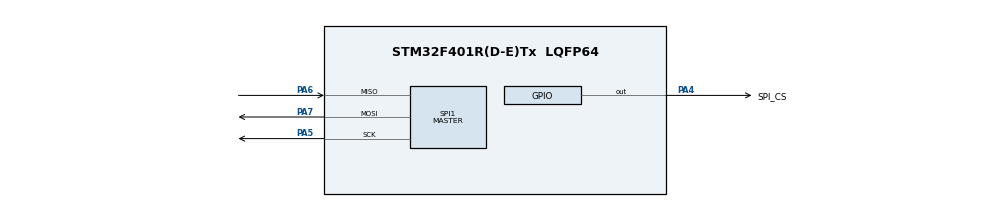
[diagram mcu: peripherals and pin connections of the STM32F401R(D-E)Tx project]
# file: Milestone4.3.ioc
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Mcu.Family=STM32F4
Mcu.Name=STM32F401R(D-E)Tx
Mcu.Package=LQFP64
NVIC.PriorityGroup=NVIC_PRIORITYGROUP_4
PA4.GPIO_Label=SPI_CS
PA4.GPIO_Speed=GPIO_SPEED_FREQ_VERY_HIGH
PA4.PinState=GPIO_PIN_SET
PA4.Signal=GPIO_Output
PA5.Mode=Full_Duplex_Master
PA5.Signal=SPI1_SCK
PA6.Mode=Full_Duplex_Master
PA6.Signal=SPI1_MISO
PA7.Mode=Full_Duplex_Master
PA7.Signal=SPI1_MOSI
ProjectManager.HeapSize=0x200
ProjectManager.StackSize=0x400
ProjectManager.TargetToolchain=Makefile
RCC.AHBFreq_Value=16000000
RCC.APB1Freq_Value=16000000
RCC.APB2Freq_Value=16000000
RCC.CortexFreq_Value=16000000
RCC.HSE_VALUE=25000000
RCC.HSI_VALUE=16000000
RCC.LSE_VALUE=32768
RCC.SYSCLKFreq_VALUE=16000000
RCC.VCOOutputFreq_Value=192000000
SPI1.Direction=SPI_DIRECTION_2LINES
SPI1.Mode=SPI_MODE_MASTER
SPI1.VirtualType=VM_MASTER
board=custom

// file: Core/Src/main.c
/* USER CODE BEGIN Header */
/**
  ******************************************************************************
  * @file           : main.c
  * @brief          : Main program body
  ******************************************************************************
  * @attention
  *
  * Copyright (c) 2026 STMicroelectronics.
  * All rights reserved.
  *
  * This software is licensed under terms that can be found in the LICENSE file
  * in the root directory of this software component.
  * If no LICENSE file comes with this software, it is provided AS-IS.
  *
  ******************************************************************************
  */
/* USER CODE END Header */
#include "main.h"

void SystemClock_Config(void);
static void MX_GPIO_Init(void);
static void MX_SPI1_Init(void);

int main(void)
{

  /* MCU Configuration--------------------------------------------------------*/

  /* Reset of all peripherals, Initializes the Flash interface and the Systick. */
  LL_APB2_GRP1_EnableClock(LL_APB2_GRP1_PERIPH_SYSCFG);
  LL_APB1_GRP1_EnableClock(LL_APB1_GRP1_PERIPH_PWR);

  /* System interrupt init*/
  NVIC_SetPriorityGrouping(NVIC_PRIORITYGROUP_4);

  /* SysTick_IRQn interrupt configuration */
  NVIC_SetPriority(SysTick_IRQn, NVIC_EncodePriority(NVIC_GetPriorityGrouping(),15, 0));

  /* Configure the system clock */
  SystemClock_Config();

  /* Initialize all configured peripherals */
  MX_GPIO_Init();
  MX_SPI1_Init();
  /* USER CODE BEGIN 2 */
  LL_SPI_Enable(SPI1);
  /* USER CODE END 2 */

  const uint8_t data = 0x02;
  /* Infinite loop */
  /* USER CODE BEGIN WHILE */
  while (1)
  {
    LL_GPIO_ResetOutputPin(GPIOA, LL_GPIO_PIN_4);
    /* USER CODE END WHILE */
    while (!LL_SPI_IsActiveFlag_TXE(SPI1)){}
      LL_SPI_TransmitData8(SPI1, data);

    while (!LL_SPI_IsActiveFlag_TXE(SPI1)){}
    while (LL_SPI_IsActiveFlag_BSY(SPI1)){}
    LL_GPIO_SetOutputPin(GPIOA, LL_GPIO_PIN_4);
    LL_mDelay(2000);
  }
  /* USER CODE END 3 */
}

void SystemClock_Config(void)
{
  LL_FLASH_SetLatency(LL_FLASH_LATENCY_0);
  while(LL_FLASH_GetLatency()!= LL_FLASH_LATENCY_0)
  {
  }
  LL_PWR_SetRegulVoltageScaling(LL_PWR_REGU_VOLTAGE_SCALE2);
  LL_RCC_HSI_SetCalibTrimming(16);
  LL_RCC_HSI_Enable();

   /* Wait till HSI is ready */
  while(LL_RCC_HSI_IsReady() != 1)
  {

  }
  LL_RCC_SetAHBPrescaler(LL_RCC_SYSCLK_DIV_1);
  LL_RCC_SetAPB1Prescaler(LL_RCC_APB1_DIV_1);
  LL_RCC_SetAPB2Prescaler(LL_RCC_APB2_DIV_1);
  LL_RCC_SetSysClkSource(LL_RCC_SYS_CLKSOURCE_HSI);

   /* Wait till System clock is ready */
  while(LL_RCC_GetSysClkSource() != LL_RCC_SYS_CLKSOURCE_STATUS_HSI)
  {

  }
  LL_Init1msTick(16000000);
  LL_SetSystemCoreClock(16000000);
  LL_RCC_SetTIMPrescaler(LL_RCC_TIM_PRESCALER_TWICE);
}

static void MX_SPI1_Init(void)
{

  LL_SPI_InitTypeDef SPI_InitStruct = {0};

  LL_GPIO_InitTypeDef GPIO_InitStruct = {0};

  /* Peripheral clock enable */
  LL_APB2_GRP1_EnableClock(LL_APB2_GRP1_PERIPH_SPI1);

  LL_AHB1_GRP1_EnableClock(LL_AHB1_GRP1_PERIPH_GPIOA);
  /**SPI1 GPIO Configuration
  PA5   ------> SPI1_SCK
  PA6   ------> SPI1_MISO
  PA7   ------> SPI1_MOSI
  */
  GPIO_InitStruct.Pin = LL_GPIO_PIN_5|LL_GPIO_PIN_6|LL_GPIO_PIN_7;
  GPIO_InitStruct.Mode = LL_GPIO_MODE_ALTERNATE;
  GPIO_InitStruct.Speed = LL_GPIO_SPEED_FREQ_VERY_HIGH;
  GPIO_InitStruct.OutputType = LL_GPIO_OUTPUT_PUSHPULL;
  GPIO_InitStruct.Pull = LL_GPIO_PULL_NO;
  GPIO_InitStruct.Alternate = LL_GPIO_AF_5;
  LL_GPIO_Init(GPIOA, &GPIO_InitStruct);

  /* SPI1 parameter configuration*/
  SPI_InitStruct.TransferDirection = LL_SPI_FULL_DUPLEX;
  SPI_InitStruct.Mode = LL_SPI_MODE_MASTER;
  SPI_InitStruct.DataWidth = LL_SPI_DATAWIDTH_8BIT;
  SPI_InitStruct.ClockPolarity = LL_SPI_POLARITY_LOW;
  SPI_InitStruct.ClockPhase = LL_SPI_PHASE_1EDGE;
  SPI_InitStruct.NSS = LL_SPI_NSS_SOFT;
  SPI_InitStruct.BaudRate = LL_SPI_BAUDRATEPRESCALER_DIV256;
  SPI_InitStruct.BitOrder = LL_SPI_MSB_FIRST;
  SPI_InitStruct.CRCCalculation = LL_SPI_CRCCALCULATION_DISABLE;
  SPI_InitStruct.CRCPoly = 10;
  LL_SPI_Init(SPI1, &SPI_InitStruct);
  LL_SPI_SetStandard(SPI1, LL_SPI_PROTOCOL_MOTOROLA);

}

static void MX_GPIO_Init(void)
{
  LL_GPIO_InitTypeDef GPIO_InitStruct = {0};

  /* GPIO Ports Clock Enable */
  LL_AHB1_GRP1_EnableClock(LL_AHB1_GRP1_PERIPH_GPIOA);

  /**/
  LL_GPIO_SetOutputPin(SPI_CS_GPIO_Port, SPI_CS_Pin);

  /**/
  GPIO_InitStruct.Pin = SPI_CS_Pin;
  GPIO_InitStruct.Mode = LL_GPIO_MODE_OUTPUT;
  GPIO_InitStruct.Speed = LL_GPIO_SPEED_FREQ_VERY_HIGH;
  GPIO_InitStruct.OutputType = LL_GPIO_OUTPUT_PUSHPULL;
  GPIO_InitStruct.Pull = LL_GPIO_PULL_NO;
  LL_GPIO_Init(SPI_CS_GPIO_Port, &GPIO_InitStruct);

}

void Error_Handler(void)
{
  __disable_irq();
  while (1)
  {
  }
}
